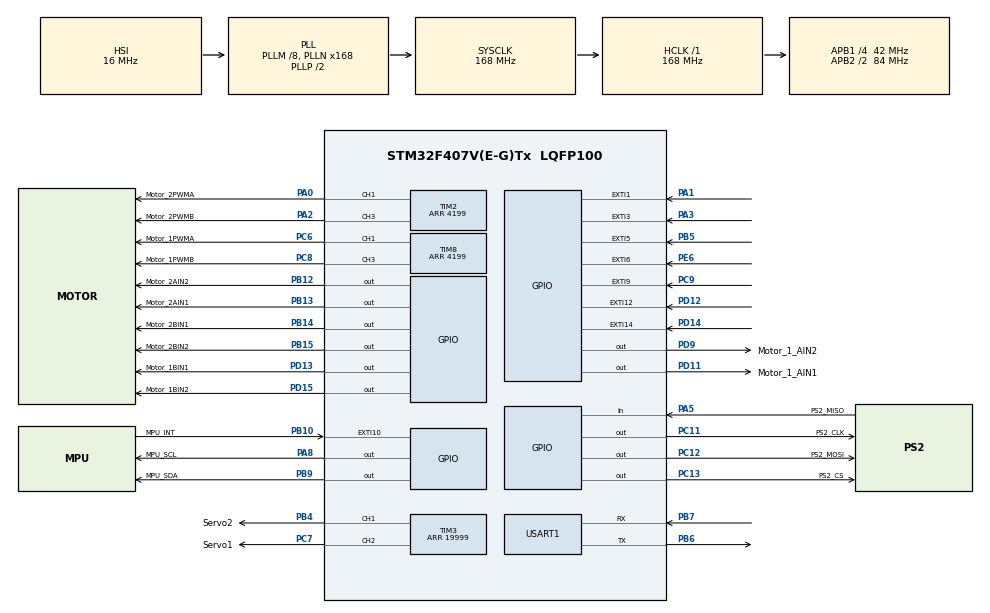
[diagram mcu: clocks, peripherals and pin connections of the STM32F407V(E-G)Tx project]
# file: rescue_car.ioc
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Mcu.Family=STM32F4
Mcu.Name=STM32F407V(E-G)Tx
Mcu.Package=LQFP100
NVIC.EXTI15_10_IRQn=true\:0\:0\:false\:false\:true\:true\:true\:true
NVIC.EXTI1_IRQn=true\:0\:0\:false\:false\:true\:true\:true\:true
NVIC.EXTI3_IRQn=true\:0\:0\:false\:false\:true\:true\:true\:true
NVIC.EXTI9_5_IRQn=true\:0\:0\:false\:false\:true\:true\:true\:true
NVIC.PriorityGroup=NVIC_PRIORITYGROUP_4
NVIC.TIM8_TRG_COM_TIM14_IRQn=true\:15\:0\:false\:false\:true\:false\:true\:true
NVIC.TimeBase=TIM8_TRG_COM_TIM14_IRQn
NVIC.TimeBaseIP=TIM14
PA0-WKUP.GPIO_Label=Motor_2PWMA
PA0-WKUP.GPIO_Speed=GPIO_SPEED_FREQ_HIGH
PA0-WKUP.Signal=S_TIM2_CH1_ETR
PA1.GPIO_ModeDefaultEXTI=GPIO_MODE_IT_RISING_FALLING
PA1.GPIO_PuPd=GPIO_PULLUP
PA1.Signal=GPXTI1
PA13.Mode=Serial_Wire
PA13.Signal=SYS_JTMS-SWDIO
PA14.Mode=Serial_Wire
PA14.Signal=SYS_JTCK-SWCLK
PA2.GPIO_Label=Motor_2PWMB
PA2.GPIO_Speed=GPIO_SPEED_FREQ_HIGH
PA2.Signal=S_TIM2_CH3
PA3.GPIO_ModeDefaultEXTI=GPIO_MODE_IT_RISING_FALLING
PA3.GPIO_PuPd=GPIO_PULLUP
PA3.Signal=GPXTI3
PA5.GPIO_Label=PS2_MISO
PA5.Signal=GPIO_Input
PA8.GPIO_Label=MPU_SCL
PA8.GPIO_ModeDefaultOutputPP=GPIO_MODE_OUTPUT_OD
PA8.GPIO_PuPd=GPIO_NOPULL
PA8.GPIO_Speed=GPIO_SPEED_FREQ_HIGH
PA8.Signal=GPIO_Output
PB10.GPIO_Label=MPU_INT
PB10.GPIO_ModeDefaultEXTI=GPIO_MODE_IT_RISING
PB10.Signal=GPXTI10
PB12.GPIO_Label=Motor_2AIN2
PB12.Signal=GPIO_Output
PB13.GPIO_Label=Motor_2AIN1
PB13.Signal=GPIO_Output
PB14.GPIO_Label=Motor_2BIN1
PB14.Signal=GPIO_Output
PB15.GPIO_Label=Motor_2BIN2
PB15.Signal=GPIO_Output
PB4.GPIO_Label=Servo2
PB4.Signal=S_TIM3_CH1
PB5.GPIO_ModeDefaultEXTI=GPIO_MODE_IT_RISING_FALLING
PB5.Signal=GPXTI5
PB6.Mode=Asynchronous
PB6.Signal=USART1_TX
PB7.Mode=Asynchronous
PB7.Signal=USART1_RX
PB9.GPIO_Label=MPU_SDA
PB9.GPIO_ModeDefaultOutputPP=GPIO_MODE_OUTPUT_OD
PB9.GPIO_PuPd=GPIO_NOPULL
PB9.GPIO_Speed=GPIO_SPEED_FREQ_HIGH
PB9.Signal=GPIO_Output
PC11.GPIO_Label=PS2_CLK
PC11.GPIO_Speed=GPIO_SPEED_FREQ_HIGH
PC11.PinState=GPIO_PIN_SET
PC11.Signal=GPIO_Output
PC12.GPIO_Label=PS2_MOSI
PC12.GPIO_Speed=GPIO_SPEED_FREQ_HIGH
PC12.PinState=GPIO_PIN_SET
PC12.Signal=GPIO_Output
PC13-ANTI_TAMP.GPIO_Label=PS2_CS
PC13-ANTI_TAMP.PinState=GPIO_PIN_SET
PC13-ANTI_TAMP.Signal=GPIO_Output
PC6.GPIO_Label=Motor_1PWMA
PC6.GPIO_Speed=GPIO_SPEED_FREQ_HIGH
PC6.Signal=S_TIM8_CH1
PC7.GPIO_Label=Servo1
PC7.Signal=S_TIM3_CH2
PC8.GPIO_Label=Motor_1PWMB
PC8.GPIO_Speed=GPIO_SPEED_FREQ_HIGH
PC8.Signal=S_TIM8_CH3
PC9.GPIO_ModeDefaultEXTI=GPIO_MODE_IT_RISING_FALLING
PC9.GPIO_PuPd=GPIO_PULLUP
PC9.Signal=GPXTI9
PD11.GPIO_Label=Motor_1_AIN1
PD11.Signal=GPIO_Output
PD12.GPIO_ModeDefaultEXTI=GPIO_MODE_IT_RISING_FALLING
PD12.GPIO_PuPd=GPIO_PULLUP
PD12.Signal=GPXTI12
PD13.GPIO_Label=Motor_1BIN1
PD13.Signal=GPIO_Output
PD14.GPIO_ModeDefaultEXTI=GPIO_MODE_IT_RISING_FALLING
PD14.GPIO_PuPd=GPIO_PULLUP
PD14.Signal=GPXTI14
PD15.GPIO_Label=Motor_1BIN2
PD15.Signal=GPIO_Output
PD9.GPIO_Label=Motor_1_AIN2
PD9.Signal=GPIO_Output
PE6.GPIO_ModeDefaultEXTI=GPIO_MODE_IT_RISING_FALLING
PE6.Signal=GPXTI6
PH0-OSC_IN.Mode=HSE-External-Oscillator
PH0-OSC_IN.Signal=RCC_OSC_IN
PH1-OSC_OUT.Mode=HSE-External-Oscillator
PH1-OSC_OUT.Signal=RCC_OSC_OUT
ProjectManager.HeapSize=0x200
ProjectManager.StackSize=0x400
ProjectManager.TargetToolchain=CMake
RCC.48MHZClocksFreq_Value=84000000
RCC.AHBFreq_Value=168000000
RCC.APB1CLKDivider=RCC_HCLK_DIV4
RCC.APB1Freq_Value=42000000
RCC.APB1TimFreq_Value=84000000
RCC.APB2CLKDivider=RCC_HCLK_DIV2
RCC.APB2Freq_Value=84000000
RCC.APB2TimFreq_Value=168000000
RCC.CortexFreq_Value=168000000
RCC.HCLKFreq_Value=168000000
RCC.HSE_VALUE=25000000
RCC.HSI_VALUE=16000000
RCC.LSE_VALUE=32768
RCC.PLLM=8
RCC.PLLN=168
RCC.SYSCLKFreq_VALUE=168000000
RCC.SYSCLKSource=RCC_SYSCLKSOURCE_PLLCLK
RCC.VCOOutputFreq_Value=336000000
SH.S_TIM2_CH1_ETR.0=TIM2_CH1,PWM Generation1 CH1
SH.S_TIM2_CH3.0=TIM2_CH3,PWM Generation3 CH3
SH.S_TIM3_CH1.0=TIM3_CH1,PWM Generation1 CH1
SH.S_TIM3_CH2.0=TIM3_CH2,PWM Generation2 CH2
SH.S_TIM8_CH1.0=TIM8_CH1,PWM Generation1 CH1
SH.S_TIM8_CH3.0=TIM8_CH3,PWM Generation3 CH3
STMicroelectronics.X-CUBE-AZRTOS-F4.1.1.0.TX_APP_MEM_POOL_SIZE=20480
STMicroelectronics.X-CUBE-AZRTOS-F4.1.1.0.TX_TIMER_TICKS_PER_SECOND=1000
STMicroelectronics.X-CUBE-AZRTOS-F4.1.1.0_IsAnAzureRtosMw=true
TIM2.Channel-PWM\ Generation1\ CH1=TIM_CHANNEL_1
TIM2.Channel-PWM\ Generation3\ CH3=TIM_CHANNEL_3
TIM2.Period=4199
TIM3.Channel-PWM\ Generation1\ CH1=TIM_CHANNEL_1
TIM3.Channel-PWM\ Generation2\ CH2=TIM_CHANNEL_2
TIM3.Period=19999
TIM8.Channel-PWM\ Generation1\ CH1=TIM_CHANNEL_1
TIM8.Channel-PWM\ Generation3\ CH3=TIM_CHANNEL_3
TIM8.Period=4199
USART1.VirtualMode=VM_ASYNC
VP_SYS_VS_tim14.Mode=TIM14
board=custom

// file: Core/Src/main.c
/* USER CODE BEGIN Header */
/**
  ******************************************************************************
  * @file           : main.c
  * @brief          : Main program body
  ******************************************************************************
  * @attention
  *
  * Copyright (c) 2026 STMicroelectronics.
  * All rights reserved.
  *
  * This software is licensed under terms that can be found in the LICENSE file
  * in the root directory of this software component.
  * If no LICENSE file comes with this software, it is provided AS-IS.
  *
  ******************************************************************************
  */
/* USER CODE END Header */
#include "main.h"
#include "tim.h"
#include "usart.h"
#include "gpio.h"

/* USER CODE BEGIN Includes */
#include "tx_api.h"
#include "car_init.h"
/* USER CODE END Includes */

void SystemClock_Config(void);

int main(void)
{

  /* MCU Configuration--------------------------------------------------------*/

  /* Reset of all peripherals, Initializes the Flash interface and the Systick. */
  HAL_Init();

  /* Configure the system clock */
  SystemClock_Config();

  /* Initialize all configured peripherals */
  MX_GPIO_Init();
  MX_TIM2_Init();
  MX_TIM3_Init();
  MX_TIM8_Init();
  MX_USART1_UART_Init();
  /* USER CODE BEGIN 2 */
  tx_kernel_enter();
  /* USER CODE END 2 */

  /* Infinite loop */
  while (1)
  {

  }
}

void SystemClock_Config(void)
{
  RCC_OscInitTypeDef RCC_OscInitStruct = {0};
  RCC_ClkInitTypeDef RCC_ClkInitStruct = {0};

  /** Configure the main internal regulator output voltage
  */
  __HAL_RCC_PWR_CLK_ENABLE();
  __HAL_PWR_VOLTAGESCALING_CONFIG(PWR_REGULATOR_VOLTAGE_SCALE1);

  /** Initializes the RCC Oscillators according to the specified parameters
  * in the RCC_OscInitTypeDef structure.
  */
  RCC_OscInitStruct.OscillatorType = RCC_OSCILLATORTYPE_HSI;
  RCC_OscInitStruct.HSIState = RCC_HSI_ON;
  RCC_OscInitStruct.HSICalibrationValue = RCC_HSICALIBRATION_DEFAULT;
  RCC_OscInitStruct.PLL.PLLState = RCC_PLL_ON;
  RCC_OscInitStruct.PLL.PLLSource = RCC_PLLSOURCE_HSI;
  RCC_OscInitStruct.PLL.PLLM = 8;
  RCC_OscInitStruct.PLL.PLLN = 168;
  RCC_OscInitStruct.PLL.PLLP = RCC_PLLP_DIV2;
  RCC_OscInitStruct.PLL.PLLQ = 4;
  if (HAL_RCC_OscConfig(&RCC_OscInitStruct) != HAL_OK)
  {
    Error_Handler();
  }

  /** Initializes the CPU, AHB and APB buses clocks
  */
  RCC_ClkInitStruct.ClockType = RCC_CLOCKTYPE_HCLK|RCC_CLOCKTYPE_SYSCLK
                              |RCC_CLOCKTYPE_PCLK1|RCC_CLOCKTYPE_PCLK2;
  RCC_ClkInitStruct.SYSCLKSource = RCC_SYSCLKSOURCE_PLLCLK;
  RCC_ClkInitStruct.AHBCLKDivider = RCC_SYSCLK_DIV1;
  RCC_ClkInitStruct.APB1CLKDivider = RCC_HCLK_DIV4;
  RCC_ClkInitStruct.APB2CLKDivider = RCC_HCLK_DIV2;

  if (HAL_RCC_ClockConfig(&RCC_ClkInitStruct, FLASH_LATENCY_5) != HAL_OK)
  {
    Error_Handler();
  }
}

/* USER CODE BEGIN 4 */
void tx_application_define(void *first_unused_memory)
{
    car_init();
}
/* USER CODE END 4 */

void HAL_TIM_PeriodElapsedCallback(TIM_HandleTypeDef *htim)
{
  if (htim->Instance == TIM14)
  {
    HAL_IncTick();
  }
}

void Error_Handler(void)
{
  __disable_irq();
  while (1)
  {
  }
}
